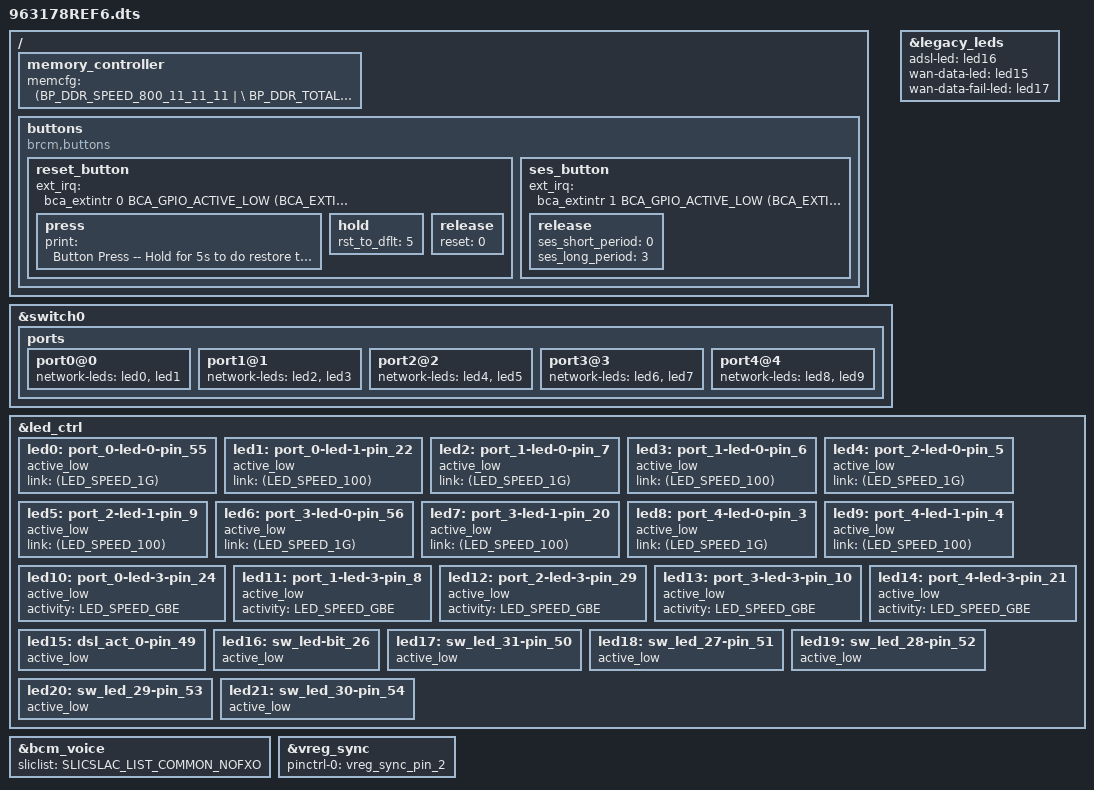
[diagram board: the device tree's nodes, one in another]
#include "63178.dtsi"
#include "../bcm_voice.dtsi"

/ {
    memory_controller {
        memcfg = <(BP_DDR_SPEED_800_11_11_11 | \
                   BP_DDR_TOTAL_SIZE_512MB   | \
                   BP_DDR_DEVICE_WIDTH_16    | \
                   BP_DDR_TOTAL_WIDTH_16BIT  | \
                   BP_DDR_63178_DEFAULT)>;
    };

	buttons {
		compatible = "brcm,buttons";
		reset_button {
			ext_irq = <&bca_extintr 0 BCA_GPIO_ACTIVE_LOW (BCA_EXTINTR_TYPE_LOW_LEVEL | BCA_EXTINTR_TYPE_SENSE_EDGE)>;
			press {
				print = "Button Press -- Hold for 5s to do restore to default";
			};
			hold {
				rst_to_dflt = <5>;
			};
			release {
				reset = <0>;
			};	
		};
		ses_button {
			ext_irq = <&bca_extintr 1 BCA_GPIO_ACTIVE_LOW (BCA_EXTINTR_TYPE_LOW_LEVEL | BCA_EXTINTR_TYPE_SENSE_EDGE)>;
			release {
				ses_short_period = <0>;
				ses_long_period = <3>;
			};
		};
	};
};
&switch0 {
        ports {
                port0@0 {
                        network-leds = <&led0 &led1>;
                        status = "okay";
                };

                port1@1 {
                        network-leds = <&led2 &led3>;
                        status = "okay";
                };

                port2@2 {
                        network-leds = <&led4 &led5>;
                        status = "okay";
                };

                port3@3 {
                        network-leds = <&led6 &led7>;
                        status = "okay";
                };

                port4@4 {
                        network-leds = <&led8 &led9>;
                        status = "okay";
                };
    };
};
&legacy_leds {
	adsl-led = <&led16>;
	wan-data-led = <&led15>;
	wan-data-fail-led = <&led17>;
};

&led_ctrl {
    led0: port_0-led-0-pin_55 {
        active_low;
        link = <(LED_SPEED_1G)>;
        status = "okay";
    };
    led1: port_0-led-1-pin_22 {
        active_low;
        link = <(LED_SPEED_100)>;
        status = "okay";
    };
    led2: port_1-led-0-pin_7 {
        active_low;
        link = <(LED_SPEED_1G)>;
        status = "okay";
    };
    led3: port_1-led-0-pin_6 {
        active_low;
        link = <(LED_SPEED_100)>;
        status = "okay";
    };
    led4: port_2-led-0-pin_5 {
        active_low;
        link = <(LED_SPEED_1G)>;
        status = "okay";
    };
    led5: port_2-led-1-pin_9 {
        active_low;
        link = <(LED_SPEED_100)>;
        status = "okay";
    };
    led6: port_3-led-0-pin_56 {
        active_low;
        link = <(LED_SPEED_1G)>;
        status = "okay";
    };
    led7: port_3-led-1-pin_20 {
        active_low;
        link = <(LED_SPEED_100)>;
        status = "okay";
    };
    led8: port_4-led-0-pin_3 {
        active_low;
        link = <(LED_SPEED_1G)>;
        status = "okay";
    };
    led9: port_4-led-1-pin_4 {
        active_low;
        link = <(LED_SPEED_100)>;
        status = "okay";
    };

    led10: port_0-led-3-pin_24 {
        active_low;
	activity = <LED_SPEED_GBE>;
        status = "okay";
    };
    led11: port_1-led-3-pin_8 {
        active_low;
	activity = <LED_SPEED_GBE>;
        status = "okay";
    };
    led12: port_2-led-3-pin_29 {
        active_low;
	activity = <LED_SPEED_GBE>;
        status = "okay";
    };
    led13: port_3-led-3-pin_10 {
        active_low;
	activity = <LED_SPEED_GBE>;
        status = "okay";
    };
    led14: port_4-led-3-pin_21 {
        active_low;
	activity = <LED_SPEED_GBE>;
        status = "okay";
    };
    led15: dsl_act_0-pin_49 {
        active_low;
        status = "okay";
    };
    led16: sw_led-bit_26 {
        active_low;
        status = "okay";
    };
    led17: sw_led_31-pin_50 {
        active_low;
        status = "okay";
    };
    led18: sw_led_27-pin_51 {
        active_low;
        status = "okay";
    };
    led19: sw_led_28-pin_52 {
        active_low;
        status = "okay";
    };
    led20: sw_led_29-pin_53 {
        active_low;
        status = "okay";
    };
    led21: sw_led_30-pin_54 {
        active_low;
        status = "okay";
    };
};
&bcm_voice{
	sliclist = SLICSLAC_LIST_COMMON_NOFXO;
};


&vreg_sync {
		pinctrl-0 = <&vreg_sync_pin_2>;
		pinctrl-names = "default";
};

